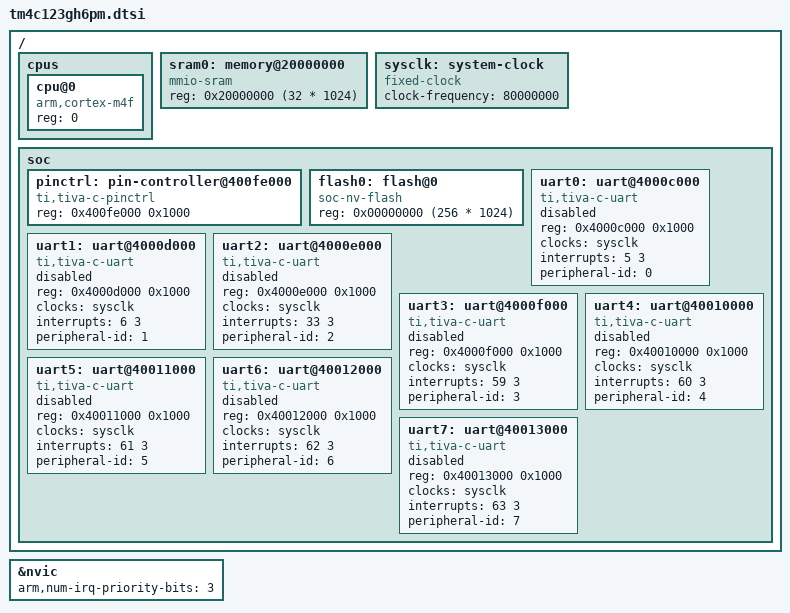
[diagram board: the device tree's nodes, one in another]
/*
 * SPDX-License-Identifier: Apache-2.0
 *
 * Copyright (c) 2026 Linumiz
 * Author: Sri Surya <srisurya@linumiz.com>
 */

/*
 * Device Tree Source include for TI TM4C123GH6PM (Tiva C Series)
 *
 * ARM Cortex-M4F, 80 MHz, 256 KB Flash, 32 KB SRAM
 * 8x UART, 4x SSI, 4x I2C, 2x CAN, USB, 12-bit ADC, etc.
 */

#include <arm/armv7-m.dtsi>

/ {
	cpus {
		#address-cells = <1>;
		#size-cells = <0>;

		cpu@0 {
			device_type = "cpu";
			compatible = "arm,cortex-m4f";
			reg = <0>;
		};
	};

	sram0: memory@20000000 {
		compatible = "mmio-sram";
		reg = <0x20000000 (32 * 1024)>;
	};

	sysclk: system-clock {
		compatible = "fixed-clock";
		clock-frequency = <80000000>;
		#clock-cells = <0>;
	};

	soc {
		pinctrl: pin-controller@400fe000 {
			compatible = "ti,tiva-c-pinctrl";
			reg = <0x400fe000 0x1000>;
		};

		flash0: flash@0 {
			compatible = "soc-nv-flash";
			reg = <0x00000000 (256 * 1024)>;
		};

		uart0: uart@4000c000 {
			compatible = "ti,tiva-c-uart";
			reg = <0x4000c000 0x1000>;
			clocks = <&sysclk>;
			interrupts = <5 3>;
			peripheral-id = <0>;
			status = "disabled";
		};

		uart1: uart@4000d000 {
			compatible = "ti,tiva-c-uart";
			reg = <0x4000d000 0x1000>;
			clocks = <&sysclk>;
			interrupts = <6 3>;
			peripheral-id = <1>;
			status = "disabled";
		};

		uart2: uart@4000e000 {
			compatible = "ti,tiva-c-uart";
			reg = <0x4000e000 0x1000>;
			clocks = <&sysclk>;
			interrupts = <33 3>;
			peripheral-id = <2>;
			status = "disabled";
		};

		uart3: uart@4000f000 {
			compatible = "ti,tiva-c-uart";
			reg = <0x4000f000 0x1000>;
			clocks = <&sysclk>;
			interrupts = <59 3>;
			peripheral-id = <3>;
			status = "disabled";
		};

		uart4: uart@40010000 {
			compatible = "ti,tiva-c-uart";
			reg = <0x40010000 0x1000>;
			clocks = <&sysclk>;
			interrupts = <60 3>;
			peripheral-id = <4>;
			status = "disabled";
		};

		uart5: uart@40011000 {
			compatible = "ti,tiva-c-uart";
			reg = <0x40011000 0x1000>;
			clocks = <&sysclk>;
			interrupts = <61 3>;
			peripheral-id = <5>;
			status = "disabled";
		};

		uart6: uart@40012000 {
			compatible = "ti,tiva-c-uart";
			reg = <0x40012000 0x1000>;
			clocks = <&sysclk>;
			interrupts = <62 3>;
			peripheral-id = <6>;
			status = "disabled";
		};

		uart7: uart@40013000 {
			compatible = "ti,tiva-c-uart";
			reg = <0x40013000 0x1000>;
			clocks = <&sysclk>;
			interrupts = <63 3>;
			peripheral-id = <7>;
			status = "disabled";
		};
	};
};

&nvic {
	arm,num-irq-priority-bits = <3>;
};
